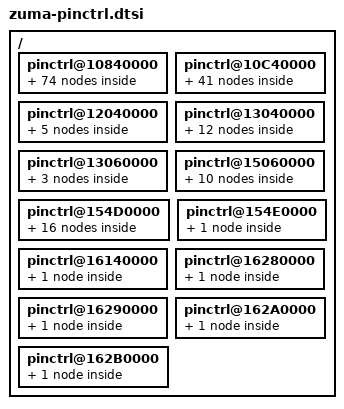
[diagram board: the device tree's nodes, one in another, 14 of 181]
// SPDX-License-Identifier: GPL-2.0-only
/*
 * Copyright 2022 Google LLC.
 *
 */

#include <dt-bindings/interrupt-controller/zuma.h>
#include <dt-bindings/pinctrl/samsung.h>
#include <dt-bindings/pinctrl/zuma.h>

/ {
	/* GPIO_PERIC0 */
	pinctrl@10840000 {
		gpp0: gpp0 {
			gpio-controller;
			#gpio-cells = <2>;
			interrupt-controller;
			#interrupt-cells = <3>;
		};
		gpp1: gpp1 {
			gpio-controller;
			#gpio-cells = <2>;
			interrupt-controller;
			#interrupt-cells = <3>;
		};
		gpp2: gpp2 {
			gpio-controller;
			#gpio-cells = <2>;
			interrupt-controller;
			#interrupt-cells = <3>;
		};
		gpp3: gpp3 {
			gpio-controller;
			#gpio-cells = <2>;
			interrupt-controller;
			#interrupt-cells = <3>;
		};
		gpp4: gpp4 {
			gpio-controller;
			#gpio-cells = <2>;
			interrupt-controller;
			#interrupt-cells = <3>;
		};
		gpp5: gpp5 {
			gpio-controller;
			#gpio-cells = <2>;
			interrupt-controller;
			#interrupt-cells = <3>;
		};
		gpp6: gpp6 {
			gpio-controller;
			#gpio-cells = <2>;
			interrupt-controller;
			#interrupt-cells = <3>;
		};
		gpp7: gpp7 {
			gpio-controller;
			#gpio-cells = <2>;
			interrupt-controller;
			#interrupt-cells = <3>;
		};
		gpp8: gpp8 {
			gpio-controller;
			#gpio-cells = <2>;
			interrupt-controller;
			#interrupt-cells = <3>;
		};
		gpp9: gpp9 {
			gpio-controller;
			#gpio-cells = <2>;
			interrupt-controller;
			#interrupt-cells = <3>;
		};
		gpp10: gpp10 {
			gpio-controller;
			#gpio-cells = <2>;
			interrupt-controller;
			#interrupt-cells = <3>;
		};
		gpp11: gpp11 {
			gpio-controller;
			#gpio-cells = <2>;
			interrupt-controller;
			#interrupt-cells = <3>;
		};
		gpp12: gpp12 {
			gpio-controller;
			#gpio-cells = <2>;
			interrupt-controller;
			#interrupt-cells = <3>;
		};
		gpp13: gpp13 {
			gpio-controller;
			#gpio-cells = <2>;
			interrupt-controller;
			#interrupt-cells = <3>;
		};
		gpp14: gpp14 {
			gpio-controller;
			#gpio-cells = <2>;
			interrupt-controller;
			#interrupt-cells = <3>;
		};
		gpp15: gpp15 {
			gpio-controller;
			#gpio-cells = <2>;
			interrupt-controller;
			#interrupt-cells = <3>;
		};
		gpp17: gpp17 {
			gpio-controller;
			#gpio-cells = <2>;
			interrupt-controller;
			#interrupt-cells = <3>;
		};
		gpp16: gpp16 {
			gpio-controller;
			#gpio-cells = <2>;
			interrupt-controller;
			#interrupt-cells = <3>;
		};

		uart0_bus: uart0-bus {
			samsung,pins = "gpp1-2", "gpp1-3";
			samsung,pin-function = <2>;
			samsung,pin-pud = <0>;
		};

		/* DECON_TE */
		disp_te_pri_on: disp-te-pri-on {
			samsung,pins = "gpp0-3";
			samsung,pin-function = <0xf>;
		};

		disp_te_pri_off: disp-te-pri-off {
			samsung,pins = "gpp0-3";
			samsung,pin-function = <0>;
		};

		disp_te_sec_on: disp-te-sec-on {
			samsung,pins = "gpp0-4";
			samsung,pin-function = <0xf>;
		};

		disp_te_sec_off: disp-te-sec-off {
			samsung,pins = "gpp0-4";
			samsung,pin-function = <0>;
		};


		/* CAM_MCLK1 */
		sensor_mclk1_out: sensor-mclk1-out {
			samsung,pins = "gpp3-0";
			samsung,pin-function = <EXYNOS_PIN_FUNC_OUTPUT>;
			samsung,pin-pud = <EXYNOS_PIN_PULL_DOWN>;
			samsung,pin-drv = <ZUMA_PIN_DRV_X2>;
		};
		sensor_mclk1_fn: sensor-mclk1-fn {
			samsung,pins = "gpp3-0";
			samsung,pin-function = <EXYNOS_PIN_FUNC_2>;
			samsung,pin-pud = <EXYNOS_PIN_PULL_NONE>;
			samsung,pin-drv = <ZUMA_PIN_DRV_X2>;
		};

		/* CAM_MCLK2 */
		sensor_mclk2_out: sensor-mclk2-out {
			samsung,pins = "gpp5-0";
			samsung,pin-function = <EXYNOS_PIN_FUNC_OUTPUT>;
			samsung,pin-pud = <EXYNOS_PIN_PULL_DOWN>;
			samsung,pin-drv = <ZUMA_PIN_DRV_X2>;
		};

		sensor_mclk2_fn: sensor-mclk2-fn {
			samsung,pins = "gpp5-0";
			samsung,pin-function = <EXYNOS_PIN_FUNC_2>;
			samsung,pin-pud = <EXYNOS_PIN_PULL_NONE>;
			samsung,pin-drv = <ZUMA_PIN_DRV_X2>;
		};

		/* CAM_MCLK3 */
		sensor_mclk3_out: sensor-mclk3-out {
			samsung,pins = "gpp7-0";
			samsung,pin-function = <EXYNOS_PIN_FUNC_OUTPUT>;
			samsung,pin-pud = <EXYNOS_PIN_PULL_DOWN>;
			samsung,pin-drv = <ZUMA_PIN_DRV_X2>;
		};

		sensor_mclk3_fn: sensor-mclk3-fn {
			samsung,pins = "gpp7-0";
			samsung,pin-function = <EXYNOS_PIN_FUNC_2>;
			samsung,pin-pud = <EXYNOS_PIN_PULL_NONE>;
			samsung,pin-drv = <ZUMA_PIN_DRV_X2>;
		};

		/* CAM_MCLK4 */
		sensor_mclk4_out: sensor-mclk4-out {
			samsung,pins = "gpp9-0";
			samsung,pin-function = <EXYNOS_PIN_FUNC_OUTPUT>;
			samsung,pin-pud = <EXYNOS_PIN_PULL_DOWN>;
			samsung,pin-drv = <ZUMA_PIN_DRV_X2>;
		};

		sensor_mclk4_fn: sensor-mclk4-fn {
			samsung,pins = "gpp9-0";
			samsung,pin-function = <EXYNOS_PIN_FUNC_2>;
			samsung,pin-pud = <EXYNOS_PIN_PULL_NONE>;
			samsung,pin-drv = <ZUMA_PIN_DRV_X2>;
		};

		/* CAM_MCLK5 */
		sensor_mclk5_out: sensor-mclk5-out {
			samsung,pins = "gpp11-0";
			samsung,pin-function = <EXYNOS_PIN_FUNC_OUTPUT>;
			samsung,pin-pud = <EXYNOS_PIN_PULL_DOWN>;
			samsung,pin-drv = <ZUMA_PIN_DRV_X2>;
		};

		sensor_mclk5_fn: sensor-mclk5-fn {
			samsung,pins = "gpp11-0";
			samsung,pin-function = <EXYNOS_PIN_FUNC_2>;
			samsung,pin-pud = <EXYNOS_PIN_PULL_NONE>;
			samsung,pin-drv = <ZUMA_PIN_DRV_X2>;
		};

		/* CAM_MCLK6 */
		sensor_mclk6_out: sensor-mclk6-out {
			samsung,pins = "gpp13-0";
			samsung,pin-function = <EXYNOS_PIN_FUNC_OUTPUT>;
			samsung,pin-pud = <EXYNOS_PIN_PULL_DOWN>;
			samsung,pin-drv = <ZUMA_PIN_DRV_X2>;
		};

		sensor_mclk6_fn: sensor-mclk6-fn {
			samsung,pins = "gpp13-0";
			samsung,pin-function = <EXYNOS_PIN_FUNC_2>;
			samsung,pin-pud = <EXYNOS_PIN_PULL_NONE>;
			samsung,pin-drv = <ZUMA_PIN_DRV_X2>;
		};

		/* CAM_MCLK7 */
		sensor_mclk7_out: sensor-mclk7-out {
			samsung,pins = "gpp14-0";
			samsung,pin-function = <EXYNOS_PIN_FUNC_OUTPUT>;
			samsung,pin-pud = <EXYNOS_PIN_PULL_DOWN>;
			samsung,pin-drv = <ZUMA_PIN_DRV_X2>;
		};

		sensor_mclk7_fn: sensor-mclk7-fn {
			samsung,pins = "gpp14-0";
			samsung,pin-function = <EXYNOS_PIN_FUNC_2>;
			samsung,pin-pud = <EXYNOS_PIN_PULL_NONE>;
			samsung,pin-drv = <ZUMA_PIN_DRV_X2>;
		};

		/* CAM_MCLK8 */
		sensor_mclk8_out: sensor-mclk8-out {
			samsung,pins = "gpp15-0";
			samsung,pin-function = <EXYNOS_PIN_FUNC_OUTPUT>;
			samsung,pin-pud = <EXYNOS_PIN_PULL_DOWN>;
			samsung,pin-drv = <ZUMA_PIN_DRV_X2>;
			samsung,pin-con-pdn = <EXYNOS_PIN_PDN_OUT0>;
			samsung,pin-pud-pdn = <EXYNOS_PIN_PULL_NONE>;
		};

		sensor_mclk8_fn: sensor-mclk8-fn {
			samsung,pins = "gpp15-0";
			samsung,pin-function = <EXYNOS_PIN_FUNC_2>;
			samsung,pin-pud = <EXYNOS_PIN_PULL_NONE>;
			samsung,pin-drv = <ZUMA_PIN_DRV_X2>;
		};

		hsi2c14_bus: hsi2c14-bus {
			samsung,pins = "gpp16-0", "gpp16-1";
			samsung,pin-function = <2>;
			samsung,pin-pud = <0>;
			samsung,pin-drv = <ZUMA_PIN_DRV_X1>;
		};

		uart14_bus_single: uart14-bus {
			samsung,pins = "gpp16-0", "gpp16-1",
					"gpp16-2", "gpp16-3";
			samsung,pin-function = <2>;
			samsung,pin-pud = <0>;
		};

		spi14_bus: spi14-bus {
			samsung,pins = "gpp16-0", "gpp16-1", "gpp16-2";
			samsung,pin-function = <2>;
			samsung,pin-pud = <0>;
			samsung,pin-drv = <ZUMA_PIN_DRV_X1>;
		};

		spi14_cs: spi14-cs {
			samsung,pins = "gpp16-3";
			samsung,pin-function = <1>;
			samsung,pin-pud = <0>;
			samsung,pin-drv = <ZUMA_PIN_DRV_X1>;
		};

		spi14_cs_func: spi14-cs-func {
			samsung,pins = "gpp16-3";
			samsung,pin-function = <2>;
			samsung,pin-pud = <0>;
			samsung,pin-drv = <ZUMA_PIN_DRV_X1>;
		};

		hsi2c6_bus: hsi2c6-bus {
			samsung,pins = "gpp12-0", "gpp12-1";
			samsung,pin-function = <EXYNOS_PIN_FUNC_3>;
			samsung,pin-pud = <EXYNOS_PIN_PULL_NONE>;
			samsung,pin-drv = <ZUMA_PIN_DRV_X1>;
			samsung,pin-pud-pdn = <EXYNOS_PIN_PDN_OUT0>;
		};

		uart6_bus_single: uart6-bus {
			samsung,pins = "gpp12-0", "gpp12-1", "gpp12-2",
			   "gpp12-3";
			samsung,pin-function = <3>;
			samsung,pin-pud = <0>;
		};

		spi6_bus: spi6-bus {
			samsung,pins = "gpp12-0", "gpp12-1", "gpp12-2";
			samsung,pin-function = <3>;
			samsung,pin-pud = <0>;
			samsung,pin-drv = <ZUMA_PIN_DRV_X1>;
		};

		spi6_cs: spi6-cs {
			samsung,pins = "gpp12-3";
			samsung,pin-function = <1>;
			samsung,pin-pud = <0>;
			samsung,pin-drv = <ZUMA_PIN_DRV_X1>;
		};

		spi6_cs_func: spi6-cs-func {
			samsung,pins = "gpp12-3";
			samsung,pin-function = <3>;
			samsung,pin-pud = <0>;
			samsung,pin-drv = <ZUMA_PIN_DRV_X1>;
		};

		hsi2c5_bus: hsi2c5-bus {
			samsung,pins = "gpp10-0", "gpp10-1";
			samsung,pin-function = <EXYNOS_PIN_FUNC_3>;
			samsung,pin-pud = <EXYNOS_PIN_PULL_NONE>;
			samsung,pin-drv = <ZUMA_PIN_DRV_X1>;
			samsung,pin-pud-pdn = <EXYNOS_PIN_PDN_OUT0>;
		};

		uart5_bus_single: uart5-bus {
			samsung,pins = "gpp10-0", "gpp10-1", "gpp10-2",
			   "gpp10-3";
			samsung,pin-function = <EXYNOS_PIN_FUNC_3>;
			samsung,pin-pud = <EXYNOS_PIN_PULL_NONE>;
			samsung,pin-drv = <ZUMA_PIN_DRV_X1>;
			samsung,pin-pud-pdn = <EXYNOS_PIN_PDN_OUT0>;
		};

		spi5_bus: spi5-bus {
			samsung,pins = "gpp10-0", "gpp10-1", "gpp10-2";
			samsung,pin-function = <3>;
			samsung,pin-pud = <0>;
			samsung,pin-drv = <ZUMA_PIN_DRV_X1>;
		};

		spi5_cs: spi5-cs {
			samsung,pins = "gpp10-3";
			samsung,pin-function = <1>;
			samsung,pin-pud = <0>;
			samsung,pin-drv = <ZUMA_PIN_DRV_X1>;
		};

		spi5_cs_func: spi5-cs-func {
			samsung,pins = "gpp10-3";
			samsung,pin-function = <3>;
			samsung,pin-pud = <0>;
			samsung,pin-drv = <ZUMA_PIN_DRV_X1>;
		};

		hsi2c4_bus: hsi2c4-bus {
			samsung,pins = "gpp8-0", "gpp8-1";
			samsung,pin-function = <EXYNOS_PIN_FUNC_3>;
			samsung,pin-pud = <EXYNOS_PIN_PULL_NONE>;
			samsung,pin-drv = <ZUMA_PIN_DRV_X1>;
			samsung,pin-pud-pdn = <EXYNOS_PIN_PDN_OUT0>;
		};

		uart4_bus_single: uart4-bus {
			samsung,pins = "gpp8-0", "gpp8-1", "gpp8-2",
			   "gpp8-3";
			samsung,pin-function = <EXYNOS_PIN_FUNC_3>;
			samsung,pin-pud = <EXYNOS_PIN_PULL_NONE>;
			samsung,pin-drv = <ZUMA_PIN_DRV_X1>;
			samsung,pin-pud-pdn = <EXYNOS_PIN_PDN_OUT0>;
		};

		spi4_bus: spi4-bus {
			samsung,pins = "gpp8-0", "gpp8-1", "gpp8-2";
			samsung,pin-function = <3>;
			samsung,pin-pud = <0>;
			samsung,pin-drv = <ZUMA_PIN_DRV_X1>;
		};

		spi4_cs: spi4-cs {
			samsung,pins = "gpp8-3";
			samsung,pin-function = <1>;
			samsung,pin-pud = <0>;
			samsung,pin-drv = <ZUMA_PIN_DRV_X1>;
		};

		spi4_cs_func: spi4-cs-func {
			samsung,pins = "gpp8-3";
			samsung,pin-function = <3>;
			samsung,pin-pud = <0>;
			samsung,pin-drv = <ZUMA_PIN_DRV_X1>;
		};

		hsi2c3_bus: hsi2c3-bus {
			samsung,pins = "gpp6-0", "gpp6-1";
			samsung,pin-function = <EXYNOS_PIN_FUNC_3>;
			samsung,pin-pud = <EXYNOS_PIN_PULL_NONE>;
			samsung,pin-drv = <ZUMA_PIN_DRV_X1>;
			samsung,pin-pud-pdn = <EXYNOS_PIN_PDN_OUT0>;
		};

		uart3_bus_single: uart3-bus {
			samsung,pins = "gpp6-0", "gpp6-1", "gpp6-2",
			   "gpp6-3";
			samsung,pin-function = <EXYNOS_PIN_FUNC_3>;
			samsung,pin-pud = <EXYNOS_PIN_PULL_NONE>;
			samsung,pin-drv = <ZUMA_PIN_DRV_X1>;
			samsung,pin-pud-pdn = <EXYNOS_PIN_PDN_OUT0>;
		};

		spi3_bus: spi3-bus {
			samsung,pins = "gpp6-0", "gpp6-1", "gpp6-2";
			samsung,pin-function = <3>;
			samsung,pin-pud = <0>;
			samsung,pin-drv = <ZUMA_PIN_DRV_X1>;
		};

		spi3_cs: spi3-cs {
			samsung,pins = "gpp6-3";
			samsung,pin-function = <1>;
			samsung,pin-pud = <0>;
			samsung,pin-drv = <ZUMA_PIN_DRV_X1>;
		};

		spi3_cs_func: spi3-cs-func {
			samsung,pins = "gpp6-3";
			samsung,pin-function = <3>;
			samsung,pin-pud = <0>;
			samsung,pin-drv = <ZUMA_PIN_DRV_X1>;
		};

		hsi2c2_bus: hsi2c2-bus {
			samsung,pins = "gpp4-0", "gpp4-1";
			samsung,pin-function = <EXYNOS_PIN_FUNC_3>;
			samsung,pin-pud = <EXYNOS_PIN_PULL_NONE>;
			samsung,pin-drv = <ZUMA_PIN_DRV_X1>;
			samsung,pin-pud-pdn = <EXYNOS_PIN_PDN_OUT0>;
		};

		uart2_bus_single: uart2-bus {
			samsung,pins = "gpp4-0", "gpp4-1", "gpp4-2",
			   "gpp4-3";
			samsung,pin-function = <EXYNOS_PIN_FUNC_3>;
			samsung,pin-pud = <EXYNOS_PIN_PULL_NONE>;
			samsung,pin-drv = <ZUMA_PIN_DRV_X1>;
			samsung,pin-pud-pdn = <EXYNOS_PIN_PDN_OUT0>;
		};

		spi2_bus: spi2-bus {
			samsung,pins = "gpp4-0", "gpp4-1", "gpp4-2";
			samsung,pin-function = <3>;
			samsung,pin-pud = <0>;
			samsung,pin-drv = <ZUMA_PIN_DRV_X1>;
		};

		spi2_cs: spi2-cs {
			samsung,pins = "gpp4-3";
			samsung,pin-function = <1>;
			samsung,pin-pud = <0>;
			samsung,pin-drv = <ZUMA_PIN_DRV_X1>;
		};

		spi2_cs_func: spi2-cs-func {
			samsung,pins = "gpp4-3";
			samsung,pin-function = <3>;
			samsung,pin-pud = <0>;
			samsung,pin-drv = <ZUMA_PIN_DRV_X1>;
		};

		hsi2c1_bus: hsi2c1-bus {
			samsung,pins = "gpp2-0", "gpp2-1";
			samsung,pin-function = <EXYNOS_PIN_FUNC_3>;
			samsung,pin-pud = <EXYNOS_PIN_PULL_NONE>;
			samsung,pin-drv = <ZUMA_PIN_DRV_X1>;
			samsung,pin-pud-pdn = <EXYNOS_PIN_PDN_OUT0>;
		};

		uart1_bus_single: uart1-bus {
			samsung,pins = "gpp2-0", "gpp2-1", "gpp2-2",
			   "gpp2-3";
			samsung,pin-function = <EXYNOS_PIN_FUNC_3>;
			samsung,pin-pud = <EXYNOS_PIN_PULL_NONE>;
			samsung,pin-drv = <ZUMA_PIN_DRV_X1>;
			samsung,pin-pud-pdn = <EXYNOS_PIN_PDN_OUT0>;
		};

		spi1_bus: spi1-bus {
			samsung,pins = "gpp2-0", "gpp2-1", "gpp2-2";
			samsung,pin-function = <3>;
			samsung,pin-pud = <0>;
			samsung,pin-drv = <ZUMA_PIN_DRV_X1>;
		};

		spi1_cs: spi1-cs {
			samsung,pins = "gpp2-3";
			samsung,pin-function = <1>;
			samsung,pin-pud = <0>;
			samsung,pin-drv = <ZUMA_PIN_DRV_X1>;
		};

		spi1_cs_func: spi1-cs-func {
			samsung,pins = "gpp2-3";
			samsung,pin-function = <3>;
			samsung,pin-pud = <0>;
			samsung,pin-drv = <ZUMA_PIN_DRV_X1>;
		};
	};

	/* GPIO_PERIC1 */
	pinctrl@10C40000 {
		gpp19: gpp19 {
			gpio-controller;
			#gpio-cells = <2>;
			interrupt-controller;
			#interrupt-cells = <3>;
		};
		gpp20: gpp20 {
			gpio-controller;
			#gpio-cells = <2>;
			interrupt-controller;
			#interrupt-cells = <3>;
		};
		gpp21: gpp21 {
			gpio-controller;
			#gpio-cells = <2>;
			interrupt-controller;
			#interrupt-cells = <3>;
		};
		gpp24: gpp24 {
			gpio-controller;
			#gpio-cells = <2>;
			interrupt-controller;
			#interrupt-cells = <3>;
		};
		gpp22: gpp22 {
			gpio-controller;
			#gpio-cells = <2>;
			interrupt-controller;
			#interrupt-cells = <3>;
		};
		gpp23: gpp23 {
			gpio-controller;
			#gpio-cells = <2>;
			interrupt-controller;
			#interrupt-cells = <3>;
		};

		hsi2c13_bus: hsi2c13-bus {
			samsung,pins = "gpp23-0", "gpp23-1";
			samsung,pin-function = <2>;
			samsung,pin-pud = <0>;
			samsung,pin-drv = <ZUMA_PIN_DRV_X1>;
		};

		uart13_bus_single: uart13-bus {
			samsung,pins = "gpp23-0", "gpp23-1",
			   "gpp23-2", "gpp23-3";
			samsung,pin-function = <2>;
			samsung,pin-pud = <0>;
		};

		spi13_bus: spi13-bus {
			samsung,pins = "gpp23-0", "gpp23-1", "gpp23-2";
			samsung,pin-function = <2>;
			samsung,pin-pud = <0>;
			samsung,pin-drv = <ZUMA_PIN_DRV_X1>;
		};

		spi13_cs: spi13-cs {
			samsung,pins = "gpp23-3";
			samsung,pin-function = <1>;
			samsung,pin-pud = <0>;
			samsung,pin-drv = <ZUMA_PIN_DRV_X1>;
		};

		spi13_cs_func: spi13-cs-func {
			samsung,pins = "gpp23-3";
			samsung,pin-function = <2>;
			samsung,pin-pud = <0>;
			samsung,pin-drv = <ZUMA_PIN_DRV_X1>;
		};

		hsi2c15_bus: hsi2c15-bus {
			samsung,pins = "gpp22-0", "gpp22-1";
			samsung,pin-function = <2>;
			samsung,pin-pud = <0>;
			samsung,pin-drv = <ZUMA_PIN_DRV_X1>;
		};

		uart15_bus_single: uart15-bus {
			samsung,pins = "gpp22-0", "gpp22-1",
			   "gpp22-2", "gpp22-3";
			samsung,pin-function = <2>;
			samsung,pin-pud = <0>;
		};

		spi15_bus: spi15-bus {
			samsung,pins = "gpp22-0", "gpp22-1", "gpp22-2";
			samsung,pin-function = <2>;
			samsung,pin-pud = <0>;
			samsung,pin-drv = <ZUMA_PIN_DRV_X1>;
		};

		spi15_cs: spi15-cs {
			samsung,pins = "gpp22-3";
			samsung,pin-function = <1>;
			samsung,pin-pud = <0>;
			samsung,pin-drv = <ZUMA_PIN_DRV_X1>;
		};

		spi15_cs_func: spi15-cs-func {
			samsung,pins = "gpp22-3";
			samsung,pin-function = <2>;
			samsung,pin-pud = <0>;
			samsung,pin-drv = <ZUMA_PIN_DRV_X1>;
		};

		hsi2c12_bus: hsi2c12-bus {
			samsung,pins = "gpp21-4", "gpp21-5";
			samsung,pin-function = <2>;
			samsung,pin-pud = <0>;
			samsung,pin-drv = <ZUMA_PIN_DRV_X1>;
		};

		uart12_bus_single: uart12-bus {
			samsung,pins = "gpp21-4", "gpp21-5",
			   "gpp21-6", "gpp21-7";
			samsung,pin-function = <2>;
			samsung,pin-pud = <0>;
		};

		spi12_bus: spi12-bus {
			samsung,pins = "gpp21-4", "gpp21-5", "gpp21-6";
			samsung,pin-function = <2>;
			samsung,pin-pud = <0>;
			samsung,pin-drv = <ZUMA_PIN_DRV_X1>;
		};

		spi12_cs: spi12-cs {
			samsung,pins = "gpp21-7";
			samsung,pin-function = <1>;
			samsung,pin-pud = <0>;
			samsung,pin-drv = <ZUMA_PIN_DRV_X1>;
		};

		spi12_cs_func: spi12-cs-func {
			samsung,pins = "gpp21-7";
			samsung,pin-function = <2>;
			samsung,pin-pud = <0>;
			samsung,pin-drv = <ZUMA_PIN_DRV_X1>;
		};

		hsi2c11_bus: hsi2c11-bus {
			samsung,pins = "gpp21-0", "gpp22-1";
			samsung,pin-function = <2>;
			samsung,pin-pud = <0>;
			samsung,pin-drv = <ZUMA_PIN_DRV_X1>;
		};

		uart11_bus_single: uart11-bus {
			samsung,pins = "gpp21-0", "gpp21-1",
			   "gpp21-2", "gpp21-3";
			samsung,pin-function = <2>;
			samsung,pin-pud = <0>;
		};

		spi11_bus: spi11-bus {
			samsung,pins = "gpp21-0", "gpp21-1", "gpp21-2";
			samsung,pin-function = <2>;
			samsung,pin-pud = <0>;
			samsung,pin-drv = <ZUMA_PIN_DRV_X1>;
		};

		spi11_cs: spi11-cs {
			samsung,pins = "gpp21-3";
			samsung,pin-function = <1>;
			samsung,pin-pud = <0>;
			samsung,pin-drv = <ZUMA_PIN_DRV_X1>;
		};

		spi11_cs_func: spi11-cs-func {
			samsung,pins = "gpp21-3";
			samsung,pin-function = <2>;
			samsung,pin-pud = <0>;
			samsung,pin-drv = <ZUMA_PIN_DRV_X1>;
		};

		hsi2c10_bus: hsi2c10-bus {
			samsung,pins = "gpp20-0", "gpp20-1";
			samsung,pin-function = <2>;
			samsung,pin-pud = <0>;
			samsung,pin-drv = <ZUMA_PIN_DRV_X1>;
		};

		uart10_bus_single: uart10-bus {
			samsung,pins = "gpp20-0", "gpp20-1",
			   "gpp20-2", "gpp20-3";
			samsung,pin-function = <2>;
			samsung,pin-pud = <0>;
		};

		spi10_bus: spi10-bus {
			samsung,pins = "gpp20-0", "gpp20-1", "gpp20-2";
			samsung,pin-function = <2>;
			samsung,pin-pud = <0>;
			samsung,pin-drv = <ZUMA_PIN_DRV_X1>;
		};

		spi10_cs: spi10-cs {
			samsung,pins = "gpp20-3";
			samsung,pin-function = <1>;
			samsung,pin-pud = <0>;
			samsung,pin-drv = <ZUMA_PIN_DRV_X1>;
		};

		spi10_cs_func: spi10-cs-func {
			samsung,pins = "gpp20-3";
			samsung,pin-function = <2>;
			samsung,pin-pud = <0>;
			samsung,pin-drv = <ZUMA_PIN_DRV_X1>;
		};

		hsi2c9_bus: hsi2c9-bus {
			samsung,pins = "gpp19-4", "gpp19-5";
			samsung,pin-function = <2>;
			samsung,pin-pud = <0>;
			samsung,pin-drv = <ZUMA_PIN_DRV_X1>;
			samsung,pin-con-pdn = <3>;
			samsung,pin-pud-pdn = <0>;

		};

		uart9_bus_single: uart9-bus {
			samsung,pins = "gpp19-4", "gpp19-5",
			   "gpp19-6", "gpp19-7";
			samsung,pin-function = <2>;
			samsung,pin-pud = <0>;
		};

		spi9_bus: spi9-bus {
			samsung,pins = "gpp19-4", "gpp19-5", "gpp19-6";
			samsung,pin-function = <2>;
			samsung,pin-pud = <0>;
			samsung,pin-drv = <ZUMA_PIN_DRV_X1>;
		};

		spi9_cs: spi9-cs {
			samsung,pins = "gpp19-7";
			samsung,pin-function = <1>;
			samsung,pin-pud = <0>;
			samsung,pin-drv = <ZUMA_PIN_DRV_X1>;
		};

		spi9_cs_func: spi9-cs-func {
			samsung,pins = "gpp19-7";
			samsung,pin-function = <2>;
			samsung,pin-pud = <0>;
			samsung,pin-drv = <ZUMA_PIN_DRV_X1>;
		};

		hsi2c0_bus: hsi2c0-bus {
			samsung,pins = "gpp19-0", "gpp19-1";
			samsung,pin-function = <3>;
			samsung,pin-pud = <0>;
			samsung,pin-drv = <ZUMA_PIN_DRV_X1>;
		};

		uart0_bus_single: uart0-bus {
			samsung,pins = "gpp19-0", "gpp19-1",
			   "gpp19-2", "gpp19-3";
			samsung,pin-function = <3>;
			samsung,pin-pud = <0>;
		};

		spi0_bus: spi0-bus {
			samsung,pins = "gpp19-0", "gpp19-1", "gpp19-2";
			samsung,pin-function = <3>;
			samsung,pin-pud = <0>;
			samsung,pin-drv = <ZUMA_PIN_DRV_X1>;
		};

		spi0_cs: spi0-cs {
			samsung,pins = "gpp19-3";
			samsung,pin-function = <1>;
			samsung,pin-pud = <0>;
			samsung,pin-drv = <ZUMA_PIN_DRV_X1>;
		};

		spi0_cs_func: spi0-cs-func {
			samsung,pins = "gpp19-3";
			samsung,pin-function = <3>;
			samsung,pin-pud = <0>;
			samsung,pin-drv = <ZUMA_PIN_DRV_X1>;
		};
	};

	/* GPIO_HSI1 */
	pinctrl@12040000 {
		gph0: gph0 {
			gpio-controller;
			#gpio-cells = <2>;
			interrupt-controller;
			#interrupt-cells = <3>;
		};
		gph1: gph1 {
			gpio-controller;
			#gpio-cells = <2>;
			interrupt-controller;
			#interrupt-cells = <3>;
		};
		gph2: gph2 {
			gpio-controller;
			#gpio-cells = <2>;
			interrupt-controller;
			#interrupt-cells = <3>;
		};

		pcie0_clkreq: pcie0_clkreq {
			samsung,pins = "gph0-1";
			samsung,pin-function = <2>;
			samsung,pin-pud = <3>;
			samsung,pin-drv = <ZUMA_PIN_DRV_X4>;
			samsung,pin-con-pdn = <3>;
			samsung,pin-pud-pdn = <3>;
		};

		pcie0_perst: pcie0_perst {
			samsung,pins = "gph0-0";
			samsung,pin-function = <1>;
			samsung,pin-drv = <ZUMA_PIN_DRV_X4>;
			samsung,pin-con-pdn = <3>;
			samsung,pin-pud-pdn = <0>;
		};
	};

	/* GPIO_HSI2 */
	pinctrl@13040000 {
		gph3: gph3 {
			gpio-controller;
			#gpio-cells = <2>;
			interrupt-controller;
			#interrupt-cells = <3>;
		};
		gph4: gph4 {
			gpio-controller;
			#gpio-cells = <2>;
			interrupt-controller;
			#interrupt-cells = <3>;
		};

		sd2_clk: sd2-clk {
			samsung,pins = "gph4-0";
			samsung,pin-function = <2>;
			samsung,pin-pud = <0>;
			samsung,pin-drv = <ZUMA_PIN_DRV_X3>;
		};

		sd2_cmd: sd2-cmd {
			samsung,pins = "gph4-1";
			samsung,pin-function = <2>;
			samsung,pin-pud = <3>;
			samsung,pin-drv = <ZUMA_PIN_DRV_X3>;
		};

		sd2_bus4: sd2-bus-width4 {
			samsung,pins = "gph4-3", "gph4-4", "gph4-5";
			samsung,pin-function = <2>;
			samsung,pin-pud = <3>;
			samsung,pin-drv = <ZUMA_PIN_DRV_X3>;
		};

		sd2_bus1: sd2-bus-width1 {
			samsung,pins = "gph4-2";
			samsung,pin-function = <2>;
			samsung,pin-pud = <3>;
			samsung,pin-drv = <ZUMA_PIN_DRV_X3>;
		};

		sd2_clk_fast_slew_rate_1x: sd2-clk_fast_slew_rate_1x {
			samsung,pins = "gph4-0";
			samsung,pin-function = <2>;
			samsung,pin-pud = <0>;
			samsung,pin-drv = <ZUMA_PIN_DRV_X1>;
		};

		sd2_clk_fast_slew_rate_2x: sd2-clk_fast_slew_rate_2x {
			samsung,pins = "gph4-0";
			samsung,pin-function = <2>;
			samsung,pin-pud = <0>;
			samsung,pin-drv = <ZUMA_PIN_DRV_X2>;
		};

		sd2_clk_fast_slew_rate_3x: sd2-clk_fast_slew_rate_3x {
			samsung,pins = "gph4-0";
			samsung,pin-function = <2>;
			samsung,pin-pud = <0>;
			samsung,pin-drv = <ZUMA_PIN_DRV_X3>;
		};

		sd2_clk_fast_slew_rate_4x: sd2-clk_fast_slew_rate_4x {
			samsung,pins = "gph4-0";
			samsung,pin-function = <2>;
			samsung,pin-pud = <0>;
			samsung,pin-drv = <ZUMA_PIN_DRV_X4>;
		};

		pcie1_clkreq: pcie1_clkreq {
			samsung,pins = "gph3-1";
			samsung,pin-function = <2>;
			samsung,pin-pud = <3>;
			samsung,pin-drv = <ZUMA_PIN_DRV_X4>;
			samsung,pin-con-pdn = <3>;
			samsung,pin-pud-pdn = <3>;
		};

		pcie1_perst: pcie1_perst {
			samsung,pins = "gph3-0";
			samsung,pin-function = <1>;
			samsung,pin-drv = <ZUMA_PIN_DRV_X4>;
			samsung,pin-con-pdn = <3>;
		};
	};

	/* GPIO_HSI2UFS */
	pinctrl@13060000 {
		gph5: gph5 {
			gpio-controller;
			#gpio-cells = <2>;
			interrupt-controller;
			#interrupt-cells = <3>;
		};

		ufs_rst_n: ufs-rst-n {
			samsung,pins = "gph5-1";
			samsung,pin-function = <2>;
			samsung,pin-pud = <0>;
			samsung,pin-con-pdn = <3>;
			samsung,pin-pud-pdn = <0>;
		};

		ufs_refclk_out: ufs-refclk-out {
			samsung,pins = "gph5-0";
			samsung,pin-function = <2>;
			samsung,pin-pud = <0>;
			samsung,pin-con-pdn = <3>;
			samsung,pin-pud-pdn = <0>;
			samsung,pin-drv = <ZUMA_PIN_DRV_X3>;
			};
	};

	/* GPIO_CUSTOM_ALIVE */
	pinctrl@15060000 {
		gpn0: gpn0 {
			gpio-controller;
			#gpio-cells = <2>;
			interrupt-controller;
			#interrupt-cells = <3>;
			interrupt-parent = <&gic>;
			interrupts = <GIC_SPI IRQ_ALIVE_CUSTOM_EINT0 IRQ_TYPE_LEVEL_HIGH>;
		};
		gpn1: gpn1 {
			gpio-controller;
			#gpio-cells = <2>;
			interrupt-controller;
			#interrupt-cells = <3>;
			interrupt-parent = <&gic>;
			interrupts = <GIC_SPI IRQ_ALIVE_CUSTOM_EINT1 IRQ_TYPE_LEVEL_HIGH>;
		};
		gpn2: gpn2 {
			gpio-controller;
			#gpio-cells = <2>;
			interrupt-controller;
			#interrupt-cells = <3>;
			interrupt-parent = <&gic>;
			interrupts = <GIC_SPI IRQ_ALIVE_CUSTOM_EINT2 IRQ_TYPE_LEVEL_HIGH>;
		};
		gpn3: gpn3 {
			gpio-controller;
			#gpio-cells = <2>;
			interrupt-controller;
				#interrupt-cells = <3>;
				interrupt-parent = <&gic>;
			interrupts = <GIC_SPI IRQ_ALIVE_CUSTOM_EINT3 IRQ_TYPE_LEVEL_HIGH>;
		};
		gpn4: gpn4 {
			gpio-controller;
			#gpio-cells = <2>;
			interrupt-controller;
			#interrupt-cells = <3>;
			interrupt-parent = <&gic>;
			interrupts = <GIC_SPI IRQ_ALIVE_CUSTOM_EINT4 IRQ_TYPE_LEVEL_HIGH>;
		};
		gpn5: gpn5 {
			gpio-controller;
			#gpio-cells = <2>;
			interrupt-controller;
			#interrupt-cells = <3>;
			interrupt-parent = <&gic>;
			interrupts = <GIC_SPI IRQ_ALIVE_CUSTOM_EINT5 IRQ_TYPE_LEVEL_HIGH>;
		};
		gpn6: gpn6 {
			gpio-controller;
			#gpio-cells = <2>;
			interrupt-controller;
			#interrupt-cells = <3>;
			interrupt-parent = <&gic>;
			interrupts = <GIC_SPI IRQ_ALIVE_CUSTOM_EINT6 IRQ_TYPE_LEVEL_HIGH>;
		};
		gpn7: gpn7 {
			gpio-controller;
			#gpio-cells = <2>;
			interrupt-controller;
			#interrupt-cells = <3>;
			interrupt-parent = <&gic>;
			interrupts = <GIC_SPI IRQ_ALIVE_CUSTOM_EINT7 IRQ_TYPE_LEVEL_HIGH>;
		};
		gpn8: gpn8 {
			gpio-controller;
			#gpio-cells = <2>;
			interrupt-controller;
			#interrupt-cells = <3>;
			interrupt-parent = <&gic>;
			interrupts = <GIC_SPI IRQ_ALIVE_CUSTOM_EINT8 IRQ_TYPE_LEVEL_HIGH>;
		};
		gpn9: gpn9 {
			gpio-controller;
			#gpio-cells = <2>;
			interrupt-controller;
			#interrupt-cells = <3>;
			interrupt-parent = <&gic>;
			interrupts = <GIC_SPI IRQ_ALIVE_CUSTOM_EINT9 IRQ_TYPE_LEVEL_HIGH>;
		};
	};

	/* GPIO_ALIVE */
	pinctrl@154D0000 {
		gpa0: gpa0 {
			gpio-controller;
			#gpio-cells = <2>;
			interrupt-controller;
			#interrupt-cells = <3>;
			interrupt-parent = <&gic>;
			interrupts = <GIC_SPI IRQ_ALIVE_EINT0 IRQ_TYPE_LEVEL_HIGH>,
				     <GIC_SPI IRQ_ALIVE_EINT1 IRQ_TYPE_LEVEL_HIGH>,
				     <GIC_SPI IRQ_ALIVE_EINT2 IRQ_TYPE_LEVEL_HIGH>,
				     <GIC_SPI IRQ_ALIVE_EINT3 IRQ_TYPE_LEVEL_HIGH>;
		};
		gpa1: gpa1 {
			gpio-controller;
			#gpio-cells = <2>;
			interrupt-controller;
			#interrupt-cells = <3>;
			interrupt-parent = <&gic>;
			interrupts = <GIC_SPI IRQ_ALIVE_EINT4 IRQ_TYPE_LEVEL_HIGH>,
				     <GIC_SPI IRQ_ALIVE_EINT5 IRQ_TYPE_LEVEL_HIGH>,
				     <GIC_SPI IRQ_ALIVE_EINT6 IRQ_TYPE_LEVEL_HIGH>,
				     <GIC_SPI IRQ_ALIVE_EINT7 IRQ_TYPE_LEVEL_HIGH>,
				     <GIC_SPI IRQ_ALIVE_EINT8 IRQ_TYPE_LEVEL_HIGH>,
				     <GIC_SPI IRQ_ALIVE_EINT9 IRQ_TYPE_LEVEL_HIGH>;
		};
		gpa2: gpa2 {
			gpio-controller;
			#gpio-cells = <2>;
			interrupt-controller;
			#interrupt-cells = <3>;
			interrupt-parent = <&gic>;
			interrupts = <GIC_SPI IRQ_ALIVE_EINT10 IRQ_TYPE_LEVEL_HIGH>,
				     <GIC_SPI IRQ_ALIVE_EINT11 IRQ_TYPE_LEVEL_HIGH>,
				     <GIC_SPI IRQ_ALIVE_EINT12 IRQ_TYPE_LEVEL_HIGH>,
				     <GIC_SPI IRQ_ALIVE_EINT13 IRQ_TYPE_LEVEL_HIGH>;
		};
		gpa3: gpa3 {
			gpio-controller;
			#gpio-cells = <2>;
			interrupt-controller;
			#interrupt-cells = <3>;
			interrupt-parent = <&gic>;
			interrupts = <GIC_SPI IRQ_ALIVE_EINT14 IRQ_TYPE_LEVEL_HIGH>,
				     <GIC_SPI IRQ_ALIVE_EINT15 IRQ_TYPE_LEVEL_HIGH>,
				     <GIC_SPI IRQ_ALIVE_EINT16 IRQ_TYPE_LEVEL_HIGH>,
				     <GIC_SPI IRQ_ALIVE_EINT17 IRQ_TYPE_LEVEL_HIGH>;
		};
		gpa4: gpa4 {
			gpio-controller;
			#gpio-cells = <2>;
			interrupt-controller;
			#interrupt-cells = <3>;
			interrupt-parent = <&gic>;
			interrupts = <GIC_SPI IRQ_ALIVE_EINT18 IRQ_TYPE_LEVEL_HIGH>,
				     <GIC_SPI IRQ_ALIVE_EINT19 IRQ_TYPE_LEVEL_HIGH>;
		};
		gpa6: gpa6 {
			gpio-controller;
			#gpio-cells = <2>;
			interrupt-controller;
			#interrupt-cells = <3>;
			interrupt-parent = <&gic>;
			interrupts = <GIC_SPI IRQ_ALIVE_EINT20 IRQ_TYPE_LEVEL_HIGH>,
				     <GIC_SPI IRQ_ALIVE_EINT21 IRQ_TYPE_LEVEL_HIGH>,
				     <GIC_SPI IRQ_ALIVE_EINT22 IRQ_TYPE_LEVEL_HIGH>,
				     <GIC_SPI IRQ_ALIVE_EINT23 IRQ_TYPE_LEVEL_HIGH>,
				     <GIC_SPI IRQ_ALIVE_EINT24 IRQ_TYPE_LEVEL_HIGH>,
				     <GIC_SPI IRQ_ALIVE_EINT25 IRQ_TYPE_LEVEL_HIGH>;
		};
		gpa7: gpa7 {
			gpio-controller;
			#gpio-cells = <2>;
			interrupt-controller;
			#interrupt-cells = <3>;
			interrupt-parent = <&gic>;
			interrupts = <GIC_SPI IRQ_ALIVE_EINT26 IRQ_TYPE_LEVEL_HIGH>,
				     <GIC_SPI IRQ_ALIVE_EINT27 IRQ_TYPE_LEVEL_HIGH>,
				     <GIC_SPI IRQ_ALIVE_EINT28 IRQ_TYPE_LEVEL_HIGH>,
				     <GIC_SPI IRQ_ALIVE_EINT29 IRQ_TYPE_LEVEL_HIGH>,
				     <GIC_SPI IRQ_ALIVE_EINT30 IRQ_TYPE_LEVEL_HIGH>,
				     <GIC_SPI IRQ_ALIVE_EINT31 IRQ_TYPE_LEVEL_HIGH>,
				     <GIC_SPI IRQ_ALIVE_EINT32 IRQ_TYPE_LEVEL_HIGH>,
				     <GIC_SPI IRQ_ALIVE_EINT33 IRQ_TYPE_LEVEL_HIGH>;
		};
		gpa8: gpa8 {
			gpio-controller;
			#gpio-cells = <2>;
			interrupt-controller;
			#interrupt-cells = <3>;
			interrupt-parent = <&gic>;
			interrupts = <GIC_SPI IRQ_ALIVE_EINT34 IRQ_TYPE_LEVEL_HIGH>,
				     <GIC_SPI IRQ_ALIVE_EINT35 IRQ_TYPE_LEVEL_HIGH>,
				     <GIC_SPI IRQ_ALIVE_EINT36 IRQ_TYPE_LEVEL_HIGH>,
				     <GIC_SPI IRQ_ALIVE_EINT37 IRQ_TYPE_LEVEL_HIGH>;
		};
		gpa9: gpa9 {
			gpio-controller;
			#gpio-cells = <2>;
			interrupt-controller;
			#interrupt-cells = <3>;
			interrupt-parent = <&gic>;
			interrupts = <GIC_SPI IRQ_ALIVE_EINT38 IRQ_TYPE_LEVEL_HIGH>,
				     <GIC_SPI IRQ_ALIVE_EINT39 IRQ_TYPE_LEVEL_HIGH>,
				     <GIC_SPI IRQ_ALIVE_EINT40 IRQ_TYPE_LEVEL_HIGH>,
				     <GIC_SPI IRQ_ALIVE_EINT41 IRQ_TYPE_LEVEL_HIGH>,
				     <GIC_SPI IRQ_ALIVE_EINT42 IRQ_TYPE_LEVEL_HIGH>,
				     <GIC_SPI IRQ_ALIVE_EINT43 IRQ_TYPE_LEVEL_HIGH>,
				     <GIC_SPI IRQ_ALIVE_EINT44 IRQ_TYPE_LEVEL_HIGH>;
		};
		gpa10: gpa10 {
			gpio-controller;
			#gpio-cells = <2>;
			interrupt-controller;
			#interrupt-cells = <3>;
			interrupt-parent = <&gic>;
			interrupts = <GIC_SPI IRQ_ALIVE_EINT45 IRQ_TYPE_LEVEL_HIGH>,
				     <GIC_SPI IRQ_ALIVE_EINT46 IRQ_TYPE_LEVEL_HIGH>,
				     <GIC_SPI IRQ_ALIVE_EINT47 IRQ_TYPE_LEVEL_HIGH>,
				     <GIC_SPI IRQ_ALIVE_EINT48 IRQ_TYPE_LEVEL_HIGH>,
				     <GIC_SPI IRQ_ALIVE_EINT49 IRQ_TYPE_LEVEL_HIGH>;
		};

		uart16_bus: uart16-bus {
			samsung,pins = "gpa2-2", "gpa2-3";
			samsung,pin-function = <2>;
			samsung,pin-pud = <0>;
		};

		uart17_bus: uart17-bus {
			samsung,pins = "gpa3-0", "gpa3-1", "gpa3-2",
			"gpa3-3";
			samsung,pin-function = <2>;
			samsung,pin-pud = <0>;
		};

		uart18_bus: uart18-bus {
			samsung,pins = "gpa3-0", "gpa3-1", "gpa3-2", "gpa3-3";
			samsung,pin-function = <EXYNOS_PIN_FUNC_2>;
			samsung,pin-pud = <EXYNOS_PIN_PULL_NONE>;
		};

		uart19_bus: uart19-bus {
			samsung,pins = "gpa4-0", "gpa4-1", "gpa4-2", "gpa4-3";
			samsung,pin-function = <2>;
			samsung,pin-pud = <0>;
		};

		spi17_cs: spi17-cs {
			samsung,pins = "gpa3-3";
			samsung,pin-function = <EXYNOS_PIN_FUNC_OUTPUT>;
			samsung,pin-pud = <EXYNOS_PIN_PULL_NONE>;
			samsung,pin-drv = <ZUMA_PIN_DRV_X1>;
		};

		spi17_bus: spi17-bus {
			samsung,pins = "gpa3-0", "gpa3-1", "gpa3-2";
			samsung,pin-function = <EXYNOS_PIN_FUNC_2>;
			samsung,pin-pud = <EXYNOS_PIN_PULL_NONE>;
			samsung,pin-drv = <ZUMA_PIN_DRV_X1>;
		};
	};

	/* GPIO_FAR_ALIVE */
	pinctrl@154E0000 {
		gpa5: gpa5 {
			gpio-controller;
			#gpio-cells = <2>;
			interrupt-controller;
			#interrupt-cells = <3>;
			interrupts = <GIC_SPI IRQ_ALIVE_EINT50 IRQ_TYPE_LEVEL_HIGH>,
				     <GIC_SPI IRQ_ALIVE_EINT51 IRQ_TYPE_LEVEL_HIGH>,
				     <GIC_SPI IRQ_ALIVE_EINT52 IRQ_TYPE_LEVEL_HIGH>,
				     <GIC_SPI IRQ_ALIVE_EINT53 IRQ_TYPE_LEVEL_HIGH>,
				     <GIC_SPI IRQ_ALIVE_EINT54 IRQ_TYPE_LEVEL_HIGH>,
				     <GIC_SPI IRQ_ALIVE_EINT55 IRQ_TYPE_LEVEL_HIGH>,
				     <GIC_SPI IRQ_ALIVE_EINT56 IRQ_TYPE_LEVEL_HIGH>,
				     <GIC_SPI IRQ_ALIVE_EINT57 IRQ_TYPE_LEVEL_HIGH>;
		};
	};

	/* GPIO_GSACTRL */
	pinctrl@16140000 {
		gps4: gps4 {
			gpio-controller;
			#gpio-cells = <2>;
			interrupt-controller;
			#interrupt-cells = <3>;
		};
	};

	/* GPIO_GSACORE0 */
	pinctrl@16280000 {
		gps0: gps0 {
			gpio-controller;
			#gpio-cells = <2>;
			interrupt-controller;
			#interrupt-cells = <3>;
		};
	};

	/* GPIO_GSACORE1 */
	pinctrl@16290000 {
		gps1: gps1 {
			gpio-controller;
			#gpio-cells = <2>;
			interrupt-controller;
			#interrupt-cells = <3>;
		};
	};

	/* GPIO_GSACORE2 */
	pinctrl@162A0000 {
		gps2: gps2 {
			gpio-controller;
			#gpio-cells = <2>;
			interrupt-controller;
			#interrupt-cells = <3>;
		};
	};

	/* GPIO_GSACORE3 */
	pinctrl@162B0000 {
		gps3: gps3 {
			gpio-controller;
			#gpio-cells = <2>;
			interrupt-controller;
			#interrupt-cells = <3>;
		};
	};
};
